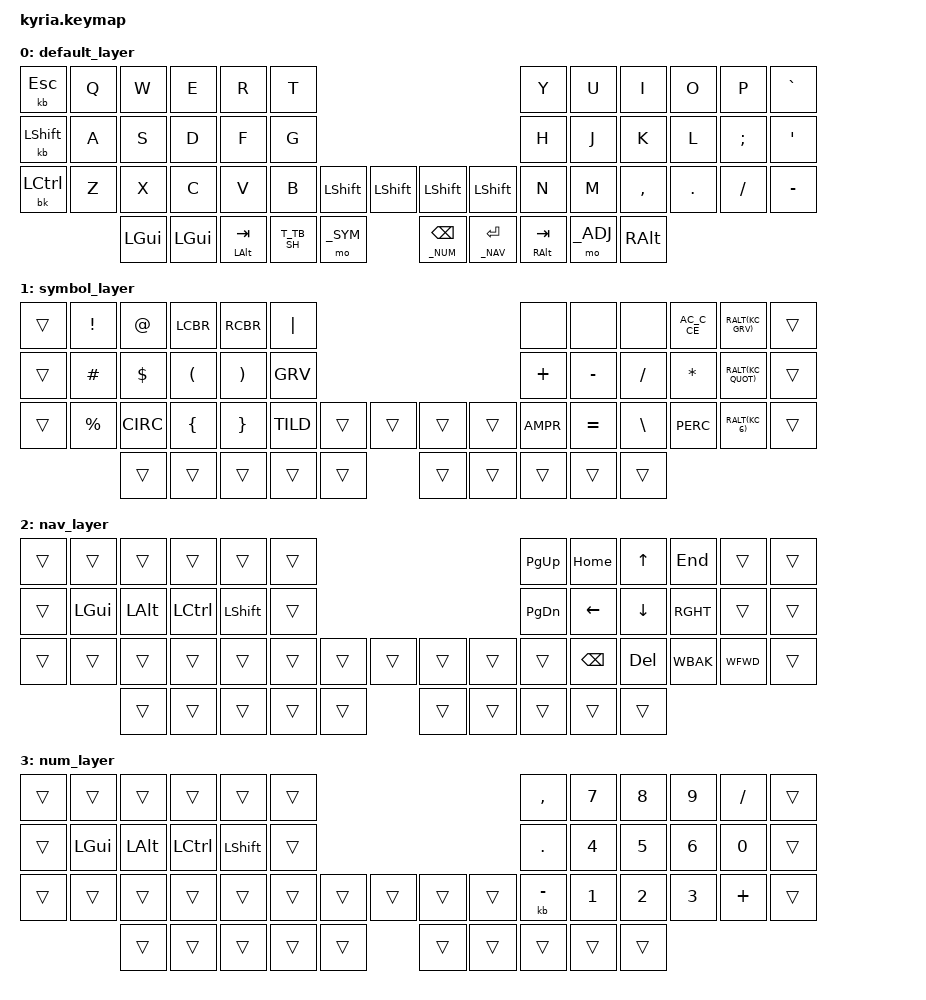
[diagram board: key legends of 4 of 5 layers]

 * Copyright (c) 2020 The ZMK Contributors
 *
 * SPDX-License-Identifier: MIT
 */

#include <behaviors.dtsi>
#include <dt-bindings/zmk/keys.h>
#include <dt-bindings/zmk/bt.h>
#include <dt-bindings/zmk/outputs.h>

#define _QWERTY 0
#define _SYM 1
#define _NAV 2
#define _NUM 3
#define _ADJ 4



/* thumb mod tap */
#define T_SP_SH &mt LSFT SPC
#define T_EN_NV &lt _NAV ENTER
#define T_TB_AG &mt RALT TAB
#define T_BS_NU &lt _NUM BSPC
#define T_TB_AL &mt LALT TAB

/* Layers */
#define L_SYM &mo _SYM
#define L_NAV &mo _NAV
#define L_NUM &mo _NUM
#define L_ADJ &mo _ADJ

/* AltGr accents */
#define AC_AIGU &kp RALT(KC_QUOT)
#define AC_GRAV &kp RALT(KC_GRV)
#define AC_CIRC &kp RALT(KC_6)



/ {
	keymap {
		compatible = "zmk,keymap";

		default_layer {
// ---------------------------------------------------------------------------------------------------------------------------------
// |  ESC  |  Q  |  W  |  E   |  R   |  T   |                                          |  Y   |  U    |  I    |  O   |   P   |   \  |
// |  TAB  |  A  |  S  |  D   |  F   |  G   |                                          |  H   |  J    |  K    |  L   |   ;   |   '  |
// | SHIFT |  Z  |  X  |  C   |  V   |  B   | L SHIFT | L SHIFT |  | L SHIFT | L SHIFT |  N   |  M    |  ,    |  .   |   /   | CTRL |
//                     | GUI  | DEL  | RET  |  SPACE  |   ESC   |  |   RET   |  SPACE  | TAB  | BSPC  | R-ALT |
			bindings = <
        &kb ESC   &kp Q &kp W &kp E &kp R &kp T                                                 &kp Y    &kp U  &kp I     &kp O   &kp P    &kp GRAVE
        &kb LSHFT &kp A &kp S &kp D &kp F &kp G                                                 &kp H    &kp J  &kp K     &kp L   &kp SEMI &kp APOS
        &bk LCTRL &kp Z &kp X &kp C &kp V &kp B   &kp LSHFT &kp LSHFT      &kp LSHFT &kp LSHFT  &kp N    &kp M  &kp COMMA &kp DOT &kp FSLH &kp MINUS
	                     &kp LGUI &kp LGUI  T_TB_AL T_TB_SH   L_SYM          T_BS_NU   T_EN_NV   T_TB_AG  L_ADJ  &kp RALT
			>;
			sensor-bindings = <&inc_dec_kp C_VOL_UP C_VOL_DN &inc_dec_kp PG_UP PG_DN>;
    };
    symbol_layer {
      bindings = <                /*  */
        &trans  &kp EXCL  &kp AT    &kp LCBR  &kp RCBR  &kp PIPE                                  &none     &none      &none     AC_C_CE   AC_GRAV  &trans
        &trans  &kp HASH  &kp DLLR  &kp LPAR  &kp RPAR  &kp GRV                                   &kp PLUS  &kp MINUS  &kp SLASH &kp ASTRK AC_AIGU  &trans
        &trans  &kp PRCNT &kp CIRC  &kp LBRC  &kp RBRC  &kp TILD  &trans  &trans  &trans  &trans  &kp AMPR  &kp EQUAL  &kp BSLH  &kp PERC  AC_CIRC  &trans
                                    &trans    &trans    &trans    &trans  &trans  &trans  &trans  &trans    &trans     &trans
        >;
        sensor-bindings = <&inc_dec_kp C_VOL_UP C_VOL_DN &inc_dec_kp PG_UP PG_DN>;
    };
      nav_layer {
      bindings = <
        &trans  &trans   &trans    &trans    &trans    &trans                                  &kp PG_UP &kp HOME  &kp UP    &kp END  &trans  &trans
        &trans  &kp LGUI &kp LALT  &kp LCTL  &kp LSHFT &trans                                  &kp PG_DN &kp LEFT  &kp DOWN  &kp RGHT  &trans  &trans
        &trans  &trans   &trans    &trans    &trans    &trans  &trans  &trans  &trans  &trans  &trans    &kp BSPC  &kp DEL   &kp WBAK  &kp WFWD  &trans
                                        &trans  &trans  &trans &trans  &trans  &trans  &trans  &trans    &trans    &trans
        >;
      };
      num_layer {
        bindings = <
          &trans  &trans   &trans    &trans    &trans    &trans                                  &kp COMMA &kp N7  &kp N8   &kp N9  &kp SLASH &trans
          &trans  &kp LGUI &kp LALT  &kp LCTL  &kp LSHFT &trans                                  &kp DOT   &kp N4  &kp N5   &kp N6  &kp N0    &trans
          &trans  &trans   &trans    &trans    &trans    &trans  &trans  &trans  &trans  &trans  &kb MINUS &kp N1  &kp N2   &kp N3  &kp PLUS  &trans
                                          &trans  &trans  &trans &trans  &trans  &trans  &trans  &trans    &trans  &trans
          >;
      };
      adj_layer {
        bindings = <
          &trans  &trans   &trans    &trans    &trans    &trans                                  &kp F1   &kp F2       &kp F3     k&kp F4     &kp F5     &kp F6
          &trans  &kp LGUI &kp LALT  &kp LCTL  &kp LSHFT &trans                                  &kp F7   &kp F8       &kp F9     &kp F10    &kp F11    &kp F12
          &trans  &trans   &trans    &trans    &trans    &trans  &trans  &trans  &trans  &trans  &none    &out OUT_TOG &bt BT_NXT &bt BT_PRV &bt BT_CLR &trans
          &trans  &trans  &trans &trans  &trans  &trans  &trans  &trans    &trans  &trans
          >;
      };

  };
 };
